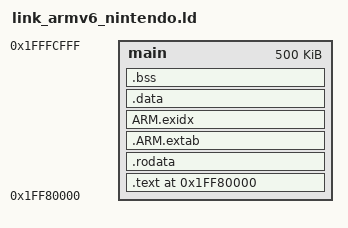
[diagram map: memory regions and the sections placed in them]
/*
* This linker script is modified to fit this projects purpose.
* The orignal linker script can found here: https://github.com/LumaTeam/Luma3DS/blob/master/arm9/linker.ld
*/
OUTPUT_FORMAT("elf32-littlearm", "elf32-bigarm", "elf32-littlearm")
OUTPUT_ARCH(arm)
ENTRY(_start)

PHDRS
{
    main PT_LOAD;
}

MEMORY
{
    main                : ORIGIN = 0x1FF80000, LENGTH = 0x1FFFD000 - 0x1FF80000
}

SECTIONS
{
    PROVIDE(__start__           = 0x1FF80000);
    PROVIDE(__stack_top__       = 0x1FFFE000);
    PROVIDE(__stack_bottom__    = 0x1FFFD000);

    . = __start__;
    .text :
    {
        /* .text */
        *(.text)
        *(.text.*)

        /* .fini */
        KEEP( *(.fini) )
        . = ALIGN(8);
    } >main :main

    .rodata :
    {
        *(.rodata)
        *(.roda)
        *(.rodata.*)
        *all.rodata*(*)
        SORT(CONSTRUCTORS)
        . = ALIGN(8);
    } >main

	/* Helps unwind callstack */
    .ARM.extab : { *(.ARM.extab* .gnu.linkonce.armextab.*) __exidx_start = ABSOLUTE(.);} >main
    ARM.exidx : { *(.ARM.exidx* .gnu.linkonce.armexidx.*)  __exidx_end = ABSOLUTE(.);} >main

    .data :
    {
        *(.data)
        *(.data.*)
        KEEP (*(.large_patch*))
        CONSTRUCTORS
        . = ALIGN(32);
    } >main

    .bss (NOLOAD) :
    {
        . = ALIGN(32);
        PROVIDE (__bss_start__ = ABSOLUTE(.));
        *(.dynbss)
        *(.bss)
        *(.bss.*)
        *(COMMON)
        . = ALIGN(8);
        PROVIDE (__bss_end__ = ABSOLUTE(.));
    } >main :NONE
    __end__ = ABSOLUTE(.) ;

    /* ==================
       ==== Metadata ====
       ================== */

    /* Discard sections that difficult post-processing */
    /DISCARD/ : { *(.group .comment .note) }

    /* Stabs debugging sections. */
    .stab          0 : { *(.stab) }
    .stabstr       0 : { *(.stabstr) }
    .stab.excl     0 : { *(.stab.excl) }
    .stab.exclstr  0 : { *(.stab.exclstr) }
    .stab.index    0 : { *(.stab.index) }
    .stab.indexstr 0 : { *(.stab.indexstr) }

    /* DWARF debug sections.
       Symbols in the DWARF debugging sections are relative to the beginning
       of the section so we begin them at 0. */

    /* DWARF 1 */
    .debug          0 : { *(.debug) }
    .line           0 : { *(.line) }

    /* GNU DWARF 1 extensions */
    .debug_srcinfo  0 : { *(.debug_srcinfo) }
    .debug_sfnames  0 : { *(.debug_sfnames) }

    /* DWARF 1.1 and DWARF 2 */
    .debug_aranges  0 : { *(.debug_aranges) }
    .debug_pubnames 0 : { *(.debug_pubnames) }

    /* DWARF 2 */
    .debug_info     0 : { *(.debug_info) }
    .debug_abbrev   0 : { *(.debug_abbrev) }
    .debug_line     0 : { *(.debug_line) }
    .debug_frame    0 : { *(.debug_frame) }
    .debug_str      0 : { *(.debug_str) }
    .debug_loc      0 : { *(.debug_loc) }
    .debug_macinfo  0 : { *(.debug_macinfo) }
}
